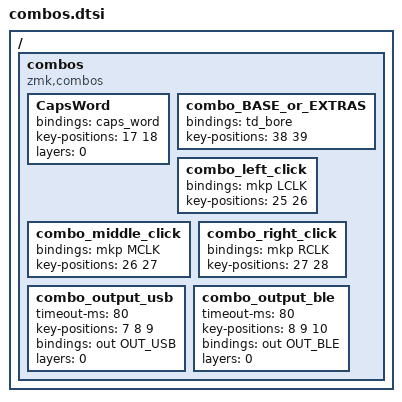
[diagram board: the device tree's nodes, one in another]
/ {
    combos {
        compatible = "zmk,combos";

        CapsWord {
            bindings = <&caps_word>;
            key-positions = <17 18>;
            layers = <0>;
        };

        combo_BASE_or_EXTRAS {
            bindings = <&td_bore>;
            key-positions = <38 39>;
        };
        
        combo_left_click {
            bindings = <&mkp LCLK>;
            key-positions = <25 26>;
        };
        
        combo_middle_click {
            bindings = <&mkp MCLK>;
            key-positions = <26 27>;
        };

        combo_right_click {
            bindings = <&mkp RCLK>;
            key-positions = <27 28>;
        };

       combo_output_usb {
           timeout-ms = <80>;
           key-positions = <7 8 9>;
           bindings = <&out OUT_USB>;
           layers = <0>;
       };

       combo_output_ble {
           timeout-ms = <80>;
           key-positions = <8 9 10>;
           bindings = <&out OUT_BLE>;
           layers = <0>;
       };
    };
};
